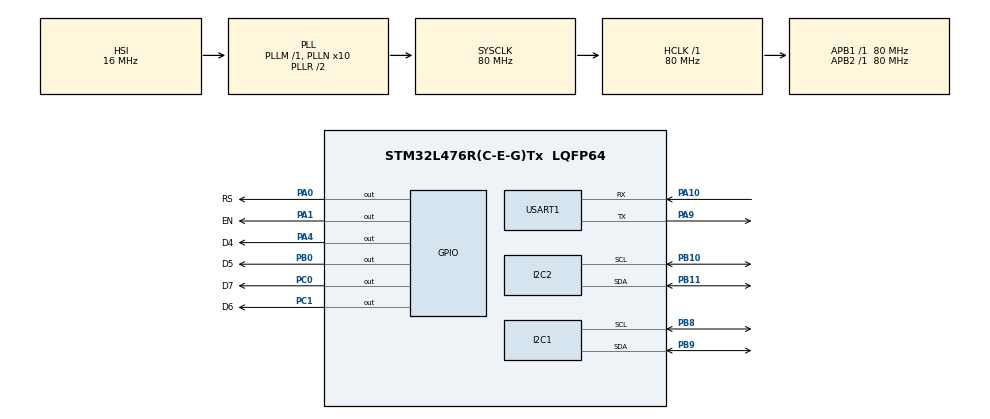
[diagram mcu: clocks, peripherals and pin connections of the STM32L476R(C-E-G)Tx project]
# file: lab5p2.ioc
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Dma.Request0=USART1_RX
Dma.Request1=USART1_TX
Dma.USART1_RX.0.Direction=DMA_PERIPH_TO_MEMORY
Dma.USART1_RX.0.Instance=DMA1_Channel5
Dma.USART1_RX.0.MemDataAlignment=DMA_MDATAALIGN_BYTE
Dma.USART1_RX.0.MemInc=DMA_MINC_ENABLE
Dma.USART1_RX.0.Mode=DMA_CIRCULAR
Dma.USART1_RX.0.PeriphDataAlignment=DMA_PDATAALIGN_BYTE
Dma.USART1_RX.0.PeriphInc=DMA_PINC_DISABLE
Dma.USART1_RX.0.Priority=DMA_PRIORITY_LOW
Dma.USART1_TX.1.Direction=DMA_MEMORY_TO_PERIPH
Dma.USART1_TX.1.Instance=DMA1_Channel4
Dma.USART1_TX.1.MemDataAlignment=DMA_MDATAALIGN_BYTE
Dma.USART1_TX.1.MemInc=DMA_MINC_ENABLE
Dma.USART1_TX.1.Mode=DMA_CIRCULAR
Dma.USART1_TX.1.PeriphDataAlignment=DMA_PDATAALIGN_BYTE
Dma.USART1_TX.1.PeriphInc=DMA_PINC_DISABLE
Dma.USART1_TX.1.Priority=DMA_PRIORITY_LOW
I2C1.Timing=0x10D19CE4
I2C2.Timing=0x10D19CE4
Mcu.Family=STM32L4
Mcu.Name=STM32L476R(C-E-G)Tx
Mcu.Package=LQFP64
NVIC.DMA1_Channel4_IRQn=true\:0\:0\:false\:false\:true\:false\:true\:true
NVIC.DMA1_Channel5_IRQn=true\:0\:0\:false\:false\:true\:false\:true\:true
NVIC.I2C2_ER_IRQn=true\:0\:0\:false\:false\:true\:true\:true\:true
NVIC.I2C2_EV_IRQn=true\:0\:0\:false\:false\:true\:true\:true\:true
NVIC.PriorityGroup=NVIC_PRIORITYGROUP_4
PA0.GPIO_Label=RS
PA0.Signal=GPIO_Output
PA1.GPIO_Label=EN
PA1.Signal=GPIO_Output
PA10.Mode=Asynchronous
PA10.Signal=USART1_RX
PA3.GPIO_Label=USART_RX
PA3.GPIO_Mode=GPIO_MODE_AF_PP
PA3.GPIO_PuPd=GPIO_NOPULL
PA3.GPIO_Speed=GPIO_SPEED_FREQ_VERY_HIGH
PA3.Signal=USART2_RX
PA4.GPIO_Label=D4
PA4.Signal=GPIO_Output
PA9.Mode=Asynchronous
PA9.Signal=USART1_TX
PB0.GPIO_Label=D5
PB0.Signal=GPIO_Output
PB10.Mode=I2C
PB10.Signal=I2C2_SCL
PB11.Mode=I2C
PB11.Signal=I2C2_SDA
PB8.Mode=I2C
PB8.Signal=I2C1_SCL
PB9.Mode=I2C
PB9.Signal=I2C1_SDA
PC0.GPIO_Label=D7
PC0.Signal=GPIO_Output
PC1.GPIO_Label=D6
PC1.Signal=GPIO_Output
ProjectManager.HeapSize=0x200
ProjectManager.StackSize=0x400
ProjectManager.TargetToolchain=STM32CubeIDE
RCC.ADCFreq_Value=64000000
RCC.AHBFreq_Value=80000000
RCC.APB1Freq_Value=80000000
RCC.APB1TimFreq_Value=80000000
RCC.APB2Freq_Value=80000000
RCC.APB2TimFreq_Value=80000000
RCC.CortexFreq_Value=80000000
RCC.HCLKFreq_Value=80000000
RCC.HSE_VALUE=8000000
RCC.HSI_VALUE=16000000
RCC.LSE_VALUE=32768
RCC.MSI_VALUE=4000000
RCC.PLLN=10
RCC.PLLSourceVirtual=RCC_PLLSOURCE_HSI
RCC.PREFETCH_ENABLE=1
RCC.SYSCLKFreq_VALUE=80000000
RCC.SYSCLKSource=RCC_SYSCLKSOURCE_PLLCLK
RCC.USBFreq_Value=64000000
RCC.VCOOutputFreq_Value=160000000
USART1.VirtualMode-Asynchronous=VM_ASYNC
board=NUCLEO-L476RG

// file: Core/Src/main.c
/* USER CODE BEGIN Header */
/**
  ******************************************************************************
  * @file           : main.c
  * @brief          : Main program body
  ******************************************************************************
  * @attention
  *
  * Copyright (c) 2025 STMicroelectronics.
  * All rights reserved.
  *
  * This software is licensed under terms that can be found in the LICENSE file
  * in the root directory of this software component.
  * If no LICENSE file comes with this software, it is provided AS-IS.
  *
  ******************************************************************************
  */
/* USER CODE END Header */
#include "main.h"

/* USER CODE BEGIN Includes */
#include "ssd1306.h"
#include "fonts.h"
/* USER CODE END Includes */

I2C_HandleTypeDef hi2c1;
I2C_HandleTypeDef hi2c2;

UART_HandleTypeDef huart1;
DMA_HandleTypeDef hdma_usart1_rx;
DMA_HandleTypeDef hdma_usart1_tx;

void SystemClock_Config(void);
static void MX_GPIO_Init(void);
static void MX_DMA_Init(void);
static void MX_USART1_UART_Init(void);
static void MX_I2C1_Init(void);
static void MX_I2C2_Init(void);

int main(void)
{

  /* MCU Configuration--------------------------------------------------------*/

  /* Reset of all peripherals, Initializes the Flash interface and the Systick. */
  HAL_Init();

  /* Configure the system clock */
  SystemClock_Config();

  /* Initialize all configured peripherals */
  MX_GPIO_Init();
  MX_DMA_Init();
  MX_USART1_UART_Init();
  MX_I2C1_Init();
  MX_I2C2_Init();
  /* USER CODE BEGIN 2 */
  SSD1306_Init (); // initialise the display
  SSD1306_GotoXY (10,10); // goto 10, 10
  SSD1306_Puts ("HELLO", &Font_11x18, 1); // print Hello
  SSD1306_GotoXY (10, 30);
  SSD1306_Puts ("WORLD !!", &Font_11x18, 1);
  SSD1306_UpdateScreen(); // update screen
  /* USER CODE END 2 */

  /* Infinite loop */
  while (1)
  {

  }
}

void SystemClock_Config(void)
{
  RCC_OscInitTypeDef RCC_OscInitStruct = {0};
  RCC_ClkInitTypeDef RCC_ClkInitStruct = {0};

  /** Configure the main internal regulator output voltage
  */
  if (HAL_PWREx_ControlVoltageScaling(PWR_REGULATOR_VOLTAGE_SCALE1) != HAL_OK)
  {
    Error_Handler();
  }

  /** Initializes the RCC Oscillators according to the specified parameters
  * in the RCC_OscInitTypeDef structure.
  */
  RCC_OscInitStruct.OscillatorType = RCC_OSCILLATORTYPE_HSI;
  RCC_OscInitStruct.HSIState = RCC_HSI_ON;
  RCC_OscInitStruct.HSICalibrationValue = RCC_HSICALIBRATION_DEFAULT;
  RCC_OscInitStruct.PLL.PLLState = RCC_PLL_ON;
  RCC_OscInitStruct.PLL.PLLSource = RCC_PLLSOURCE_HSI;
  RCC_OscInitStruct.PLL.PLLM = 1;
  RCC_OscInitStruct.PLL.PLLN = 10;
  RCC_OscInitStruct.PLL.PLLP = RCC_PLLP_DIV7;
  RCC_OscInitStruct.PLL.PLLQ = RCC_PLLQ_DIV2;
  RCC_OscInitStruct.PLL.PLLR = RCC_PLLR_DIV2;
  if (HAL_RCC_OscConfig(&RCC_OscInitStruct) != HAL_OK)
  {
    Error_Handler();
  }

  /** Initializes the CPU, AHB and APB buses clocks
  */
  RCC_ClkInitStruct.ClockType = RCC_CLOCKTYPE_HCLK|RCC_CLOCKTYPE_SYSCLK
                              |RCC_CLOCKTYPE_PCLK1|RCC_CLOCKTYPE_PCLK2;
  RCC_ClkInitStruct.SYSCLKSource = RCC_SYSCLKSOURCE_PLLCLK;
  RCC_ClkInitStruct.AHBCLKDivider = RCC_SYSCLK_DIV1;
  RCC_ClkInitStruct.APB1CLKDivider = RCC_HCLK_DIV1;
  RCC_ClkInitStruct.APB2CLKDivider = RCC_HCLK_DIV1;

  if (HAL_RCC_ClockConfig(&RCC_ClkInitStruct, FLASH_LATENCY_4) != HAL_OK)
  {
    Error_Handler();
  }
}

static void MX_I2C1_Init(void)
{

  hi2c1.Instance = I2C1;
  hi2c1.Init.Timing = 0x10D19CE4;
  hi2c1.Init.OwnAddress1 = 0;
  hi2c1.Init.AddressingMode = I2C_ADDRESSINGMODE_7BIT;
  hi2c1.Init.DualAddressMode = I2C_DUALADDRESS_DISABLE;
  hi2c1.Init.OwnAddress2 = 0;
  hi2c1.Init.OwnAddress2Masks = I2C_OA2_NOMASK;
  hi2c1.Init.GeneralCallMode = I2C_GENERALCALL_DISABLE;
  hi2c1.Init.NoStretchMode = I2C_NOSTRETCH_DISABLE;
  if (HAL_I2C_Init(&hi2c1) != HAL_OK)
  {
    Error_Handler();
  }

  /** Configure Analogue filter
  */
  if (HAL_I2CEx_ConfigAnalogFilter(&hi2c1, I2C_ANALOGFILTER_ENABLE) != HAL_OK)
  {
    Error_Handler();
  }

  /** Configure Digital filter
  */
  if (HAL_I2CEx_ConfigDigitalFilter(&hi2c1, 0) != HAL_OK)
  {
    Error_Handler();
  }

}

static void MX_I2C2_Init(void)
{

  hi2c2.Instance = I2C2;
  hi2c2.Init.Timing = 0x10D19CE4;
  hi2c2.Init.OwnAddress1 = 0;
  hi2c2.Init.AddressingMode = I2C_ADDRESSINGMODE_7BIT;
  hi2c2.Init.DualAddressMode = I2C_DUALADDRESS_DISABLE;
  hi2c2.Init.OwnAddress2 = 0;
  hi2c2.Init.OwnAddress2Masks = I2C_OA2_NOMASK;
  hi2c2.Init.GeneralCallMode = I2C_GENERALCALL_DISABLE;
  hi2c2.Init.NoStretchMode = I2C_NOSTRETCH_DISABLE;
  if (HAL_I2C_Init(&hi2c2) != HAL_OK)
  {
    Error_Handler();
  }

  /** Configure Analogue filter
  */
  if (HAL_I2CEx_ConfigAnalogFilter(&hi2c2, I2C_ANALOGFILTER_ENABLE) != HAL_OK)
  {
    Error_Handler();
  }

  /** Configure Digital filter
  */
  if (HAL_I2CEx_ConfigDigitalFilter(&hi2c2, 0) != HAL_OK)
  {
    Error_Handler();
  }

}

static void MX_USART1_UART_Init(void)
{

  huart1.Instance = USART1;
  huart1.Init.BaudRate = 115200;
  huart1.Init.WordLength = UART_WORDLENGTH_8B;
  huart1.Init.StopBits = UART_STOPBITS_1;
  huart1.Init.Parity = UART_PARITY_NONE;
  huart1.Init.Mode = UART_MODE_TX_RX;
  huart1.Init.HwFlowCtl = UART_HWCONTROL_NONE;
  huart1.Init.OverSampling = UART_OVERSAMPLING_16;
  huart1.Init.OneBitSampling = UART_ONE_BIT_SAMPLE_DISABLE;
  huart1.AdvancedInit.AdvFeatureInit = UART_ADVFEATURE_NO_INIT;
  if (HAL_UART_Init(&huart1) != HAL_OK)
  {
    Error_Handler();
  }

}

static void MX_DMA_Init(void)
{

  /* DMA controller clock enable */
  __HAL_RCC_DMA1_CLK_ENABLE();

  /* DMA interrupt init */
  /* DMA1_Channel4_IRQn interrupt configuration */
  HAL_NVIC_SetPriority(DMA1_Channel4_IRQn, 0, 0);
  HAL_NVIC_EnableIRQ(DMA1_Channel4_IRQn);
  /* DMA1_Channel5_IRQn interrupt configuration */
  HAL_NVIC_SetPriority(DMA1_Channel5_IRQn, 0, 0);
  HAL_NVIC_EnableIRQ(DMA1_Channel5_IRQn);

}

static void MX_GPIO_Init(void)
{
  GPIO_InitTypeDef GPIO_InitStruct = {0};

  /* GPIO Ports Clock Enable */
  __HAL_RCC_GPIOC_CLK_ENABLE();
  __HAL_RCC_GPIOA_CLK_ENABLE();
  __HAL_RCC_GPIOB_CLK_ENABLE();

  /*Configure GPIO pin Output Level */
  HAL_GPIO_WritePin(GPIOC, D7_Pin|D6_Pin, GPIO_PIN_RESET);

  /*Configure GPIO pin Output Level */
  HAL_GPIO_WritePin(GPIOA, RS_Pin|EN_Pin|D4_Pin, GPIO_PIN_RESET);

  /*Configure GPIO pin Output Level */
  HAL_GPIO_WritePin(D5_GPIO_Port, D5_Pin, GPIO_PIN_RESET);

  /*Configure GPIO pins : D7_Pin D6_Pin */
  GPIO_InitStruct.Pin = D7_Pin|D6_Pin;
  GPIO_InitStruct.Mode = GPIO_MODE_OUTPUT_PP;
  GPIO_InitStruct.Pull = GPIO_NOPULL;
  GPIO_InitStruct.Speed = GPIO_SPEED_FREQ_LOW;
  HAL_GPIO_Init(GPIOC, &GPIO_InitStruct);

  /*Configure GPIO pins : RS_Pin EN_Pin D4_Pin */
  GPIO_InitStruct.Pin = RS_Pin|EN_Pin|D4_Pin;
  GPIO_InitStruct.Mode = GPIO_MODE_OUTPUT_PP;
  GPIO_InitStruct.Pull = GPIO_NOPULL;
  GPIO_InitStruct.Speed = GPIO_SPEED_FREQ_LOW;
  HAL_GPIO_Init(GPIOA, &GPIO_InitStruct);

  /*Configure GPIO pin : USART_RX_Pin */
  GPIO_InitStruct.Pin = USART_RX_Pin;
  GPIO_InitStruct.Mode = GPIO_MODE_AF_PP;
  GPIO_InitStruct.Pull = GPIO_NOPULL;
  GPIO_InitStruct.Speed = GPIO_SPEED_FREQ_VERY_HIGH;
  GPIO_InitStruct.Alternate = GPIO_AF7_USART2;
  HAL_GPIO_Init(USART_RX_GPIO_Port, &GPIO_InitStruct);

  /*Configure GPIO pin : D5_Pin */
  GPIO_InitStruct.Pin = D5_Pin;
  GPIO_InitStruct.Mode = GPIO_MODE_OUTPUT_PP;
  GPIO_InitStruct.Pull = GPIO_NOPULL;
  GPIO_InitStruct.Speed = GPIO_SPEED_FREQ_LOW;
  HAL_GPIO_Init(D5_GPIO_Port, &GPIO_InitStruct);

}

void Error_Handler(void)
{
  __disable_irq();
  while (1)
  {
  }
}
